# i2c: IP-XACT component
VLNV spiritconsortium.org:Leon2RTL:i2c:1.0
I2C master controller - with enhanced register descriptions

## Bus interfaces (logical=physical port)
IPClk: slave spiritconsortium.org:busdef.clock:clock:1.0
  CLK=ip_clk
IPReset: slave spiritconsortium.org:busdef.reset:reset:1.0
  RESETn=rst_an
APBClk: slave spiritconsortium.org:busdef.clock:clock:1.0
  CLK=pclk
APBReset: slave spiritconsortium.org:busdef.reset:reset:1.0
  RESETn=presetn
ambaAPB: slave amba.com:AMBA2:APB:r2p0_4, memory map ambaAPB
  PSELx=psel, PENABLE=penable, PADDR=paddr, PWRITE=pwrite, PWDATA=pwdata, PRDATA=prdata, PCLK=pclk, PRESETn=presetn
i2c_internal: master spiritconsortium.org:busdef.nxp:i2c_internal:1.0
  SCL_IN=sclIn, SCL_OEN=sclOut, SDA_IN=sdaIn, SDA_OEN=sdaOut
interrupt: master spiritconsortium.org:busdef.interrupt:interrupt:1.0
  IRQ=intr

## Ports
in pclk
in presetn
in psel
in penable
in paddr[11:0]
in pwrite
in pwdata[31:0]
out prdata[31:0]
in sclIn
out sclOut
in sdaIn
out sdaOut
in ip_clk
in rst_an
out intr

## Address spaces and blocks
ambaAPB.registers: base 0, range 4k, width 32

## Registers
Registers are 32-bit, read-write, reset 0x0 unless marked. A register's access mark holds for its fields unless they carry their own. Offsets are from the block's base; lines under a group give offsets from that group; [hi:lo] are bit positions; {n}, {i} and the like mark numbered series; 'fields as' and 'values as' point back to an identical list; <NAME> marks a mode.

## ambaAPB.registers
Base 0x00000000
0x00 rxfifo ro — Recieve FIFO
  [7:0] Data_byte — Bit 7 is the MSB
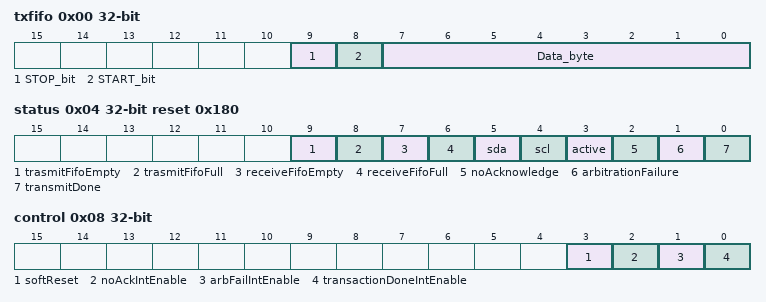
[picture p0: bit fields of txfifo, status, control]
0x00 txfifo wo — Transmit FIFO
  [9] STOP_bit — Issue a STOP condition after transmitting this data byte
  [8] START_bit — Issue a START condition before transmitting this data byte
  [7:0] Data_byte — Bit 7 is the MSB
0x04 status reset 0x180
  [9] trasmitFifoEmpty ro — Indicates that the trasmit FIFO is empty
  [8] trasmitFifoFull ro — Indicates that the trasmit FIFO is full
  [7] receiveFifoEmpty ro — Indicates that the receive FIFO is empty
  [6] receiveFifoFull ro — Indicates that the receive FIFO is full
  [5] sda ro — Indicates the current state of the sda line
  [4] scl ro — Indicates the current state of the scl line
  [3] active ro — Indicates that I2C bus is active
  [2] noAcknowledge ro — Indicates that no acknowledge was recieved on the current transmission. This bit is reset when a new transmission starts.
  [1] arbitrationFailure write-1-clears — Indicates an arbitration failure. Wite a 1 to clear this bit.
  [0] transmitDone write-1-clears — Indicates that the current transmission is complete. Write a 1 to clear this bit.
0x08 control
  [3] softReset — Soft reset of the IP
  [2] noAckIntEnable — No ackowledge interrupt enable
  [1] arbFailIntEnable — Abatration failure interrupt enable
  [0] transactionDoneIntEnable — Transaction done interrupt enable
0x0C clkDivHi 6-bit reset 0x30 — Clock high time divide register
  [5:0] clkDivHi — Clock high time divide field
0x10 clkDivLo 6-bit reset 0x30 — Clock low time divide register
  [5:0] clkDivLo — Clock low time divide field
0xFFC Module_ID ro reset 0xD02 — Contains the ID number of the IP
  [15:0] ID — Unique identification number

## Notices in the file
Copyright (c) 2005, 2006, 2007, 2008, 2009 The SPIRIT Consortium.
This work forms part of a deliverable of The SPIRIT Consortium.
Use of these materials are governed by the legal terms and conditions
outlined in the disclaimer available from www.spiritconsortium.org.
This source file is provided on an AS IS basis.  The SPIRIT
Consortium disclaims any warranty express or implied including
any warranty of merchantability and fitness for use for a
particular purpose.
The user of the source file shall indemnify and hold The SPIRIT
Consortium and its members harmless from any damages or liability.
